# A31G11x register map
Vendor: VENDOR ABOV Semiconductor Co., Ltd.; Series: A31G11x; File version: 1.0
CPU: CM0+ r0p1, little endian, no MPU, no FPU, VTOR, 2 interrupt priority bits
Registers are 32-bit, read-write, reset 0x0 unless marked. A register's access mark holds for its fields unless they carry their own. Offsets are from the block's base; [hi:lo] are bit positions; {n}, {i} and the like mark numbered series.

## LCD — LCD Driver
Base 0x40005000
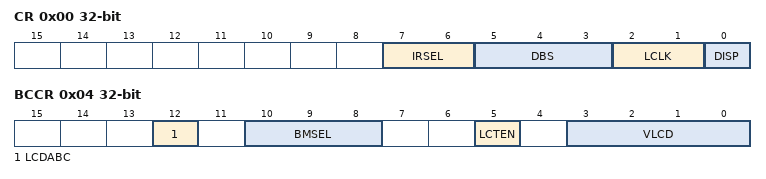
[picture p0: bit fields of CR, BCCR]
0x00 CR — LCD Driver Control Register
  [7:6] IRSEL — Internal LCD Bias Dividing Resistor Selection
    0=RLCD3 (RLCD3: 105/105/80[kohm] @(1/2)/(1/3)/(1/4) bias); 1=RLCD1 (RLCD1: 10/10/10[kohm] @(1/2)/(1/3)/(1/4) bias); 2=RLCD2 (RLCD2: 66/66/50[kohm] @(1/2)/(1/3)/(1/4) bias); 3=RLCD4 (RLCD4: 320/320/240[kohm] @(1/2)/(1/3)/(1/4) bias)
  [5:3] DBS — LCD Duty and Bias Selection
    0=Duty8Bias4 (1/8 duty, 1/4 bias); 1=Duty6Bias4 (1/6 duty, 1/4 bias); 2=Duty5Bias3 (1/5 duty, 1/3 bias); 3=Duty4Bias3 (1/4 duty, 1/3 bias); 4=Duty3Bias3 (1/3 duty, 1/3 bias); 5=Duty3Bias2 (1/3 duty, 1/2 bias)
  [2:1] LCLK — LCD Clock Selection (When fLCD = 32.768kHz)
    0=fLCD256 (128Hz); 1=fLCD128 (256Hz); 2=fLCD64 (512Hz); 3=fLCD32 (1024Hz)
  [0] DISP — LCD Display Control
    0=Off (Display off); 1=On (Normal display on)
0x04 BCCR — LCD Automatic Bias and Contrast Control Register
  [12] LCDABC — LCD Automatic Bias Control
    0=Off (LCD automatic bias is off); 1=On (LCD automatic bias is on)
  [10:8] BMSEL — 'Bias Mode A' Time Selection
    {v}=BMA{v+1}Clk ('Bias Mode A' for {v+1}-clock of fLCD) (v=0..7)
  [5] LCTEN — LCD Driver Contrast Control
    0=Disable LCD driver contrast; 1=Enable LCD driver contrast
  [3:0] VLCD — VLC0 Voltage Control when the contrast is enabled
    0=Step0 (VDD x 16/31 Step); 1=Step1 (VDD x 16/30 Step); 2=Step2 (VDD x 16/29 Step); 3=Step3 (VDD x 16/28 Step); 4=Step4 (VDD x 16/27 Step); 5=Step5 (VDD x 16/26 Step); 6=Step6 (VDD x 16/25 Step); 7=Step7 (VDD x 16/24 Step); 8=Step8 (VDD x 16/23 Step); 9=Step9 (VDD x 16/22 Step); 10=Step10 (VDD x 16/21 Step); 11=Step11 (VDD x 16/20 Step); 12=Step12 (VDD x 16/19 Step); 13=Step13 (VDD x 16/18 Step); 14=Step14 (VDD x 16/17 Step); 15=Step15 (VDD x 16/16 Step)
{0x10+i} DR{i} 8-bit reset not defined (i=0..27) — LCD Display Data Register {i}

## CRC — Cyclic Redundancy Check and Checksum
Base 0x30001000
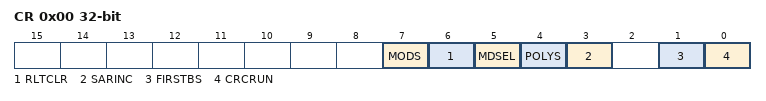
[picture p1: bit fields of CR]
0x00 CR — CRC/Checksum Control Register
  [7] MODS — User/Auto Mode Selection
    0=User Mode (Calculate every data written to the CRC_IN register); 1=Auto Mode (Calculate till CRC_SADR == CRC_EADR)
  [6] RLTCLR — CRC/Checksum Result Data Register (CRCRLT) Initialization
    0=NoEffect; 1=Initialize the CRC_RLT register with the value of CRC_INIT. (This bit is automatically cleared to '0' after operation.)
  [5] MDSEL — CRC/Checksum Selection
    0=CRC (Select CRC.); 1=Checksum (Select Checksum.)
  [4] POLYS — Polynomial Selection (CRC only)
    0=CRC16_CCITT (CRC16-CCITT (G1(x) = x16 + x12 + x5 + 1)); 1=CRC16 (CRC16 (G2(x) = x16 + x15 + x2 + 1))
  [3] SARINC — CRC/Checksum Start Address Auto Increment Control (User mode only)
    0=Disable (No effect.); 1=Enable (The CRC/Checksum start address register is incremented as the selected input size every writing to the CRC_IN register.)
  [1] FIRSTBS — First Shifted-in Selection (CRC only)
    0=msbFirst; 1=lsbFirst
  [0] CRCRUN — CRC/Checksum Start Control and Busy
    0=Stop (Not busy. The CRC operation can be finished by writing '0' to this bit while running.); 1=Start CRC operation. This bit is automatically cleared to '0' when the value of CRC_SADR register reaches the value of CRC_EADR register.
0x04 IN — CRC/Checksum Input Data Register
  [31:0] INDATA — CRC Input Data
0x08 RLT ro reset 0xFFFF — CRC/Checksum Result Data Register
  [15:0] RLTDATA — CRC Result Data
0x0C INIT — CRC/Checksum Initial Data Register
  [15:0] INIDATA — CRC Initial Data
0x10 SADR reset 0x10000000 — CRC/Checksum Start Address Register
  [31:2] SADR — CRC Start Address
0x14 EADR reset 0x1000FFFC — CRC/Checksum End Address Register
  [31:2] EADR — CRC End Address
